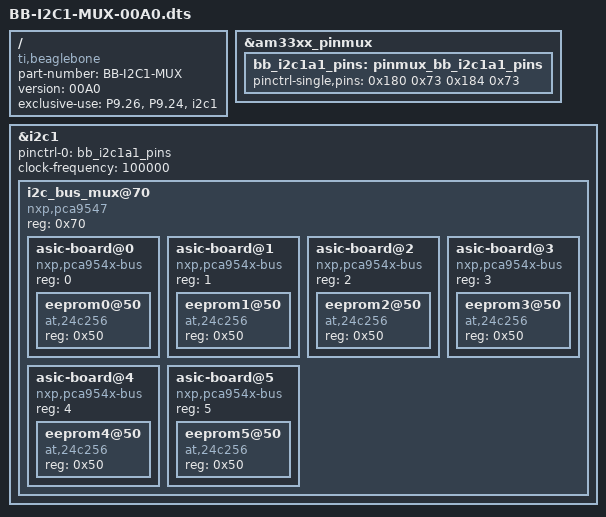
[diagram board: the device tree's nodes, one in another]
/*
 * Copyright (C) 2013 CircuitCo
 *
 * Virtual cape for I2C1 on connector pins P9.26 P9.24 (ALT config #1)
 *
 * This program is free software; you can redistribute it and/or modify
 * it under the terms of the GNU General Public License version 2 as
 * published by the Free Software Foundation.
 */
/dts-v1/;
/plugin/;

/ {
	compatible = "ti,beaglebone", "ti,beaglebone-black";

	/* identification */
	part-number = "BB-I2C1-MUX";
	version = "00A0";

	/* state the resources this cape uses */
	exclusive-use =
		/* the pin header uses */
		"P9.26",	/* i2c1_sda */
		"P9.24",	/* i2c1_scl */
		/* the hardware ip uses */
		"i2c1";

	fragment@0 {
		target = <&am33xx_pinmux>;
		__overlay__ {
			bb_i2c1a1_pins: pinmux_bb_i2c1a1_pins {
				pinctrl-single,pins = <
					0x180 0x73	/* uart1_rxd.i2c1_sda, SLEWCTRL_SLOW | INPUT_PULLUP | MODE3 */
					0x184 0x73	/* uart1_txdi2c1_scl, SLEWCTRL_SLOW | INPUT_PULLUP | MODE3 */
				>;
			};
		};
	};

	fragment@1 {
		target = <&i2c1>;	/* i2c1 is numbered correctly */
		__overlay__ {
			status = "okay";
			pinctrl-names = "default";
			pinctrl-0 = <&bb_i2c1a1_pins>;

			/* this is the configuration part */
			clock-frequency = <100000>;	

			#address-cells = <1>;
			#size-cells = <0>;

			i2c_bus_mux@70 {
				compatible = "nxp,pca9547";
				reg = <0x70>;
				#address-cells = <1>;
				#size-cells = <0>;

				asic-board@0 {
					compatible = "nxp,pca954x-bus";
					#address-cells = <1>;
					#size-cells = <0>;
					reg = <0>;

					eeprom0@50 {
						compatible = 
"at,24c256";
						reg = <0x50>;
					};
				};

				asic-board@1 {
					compatible = "nxp,pca954x-bus";
					#address-cells = <1>;
					#size-cells = <0>;
					reg = <1>;

                                        eeprom1@50 {
                                                compatible =
"at,24c256";
                                                reg = <0x50>;
                                        };
				};

				asic-board@2 {
					compatible = "nxp,pca954x-bus";
					#address-cells = <1>;
					#size-cells = <0>;
					reg = <2>;

                                        eeprom2@50 {
                                                compatible =
"at,24c256";
                                                reg = <0x50>;
                                        };
				};

                                asic-board@3 {
					compatible = "nxp,pca954x-bus";
					#address-cells = <1>;
					#size-cells = <0>;
					reg = <3>;

					eeprom3@50 {
						compatible =
"at,24c256";
						reg = <0x50>;
					};
				};

                                asic-board@4 {
                                        compatible = "nxp,pca954x-bus";
                                        #address-cells = <1>;
                                        #size-cells = <0>;
                                        reg = <4>;

                                        eeprom4@50 {
                                                compatible =
"at,24c256";
                                                reg = <0x50>;
                                        };
				};

                                asic-board@5 {
                                        compatible = "nxp,pca954x-bus";
                                        #address-cells = <1>;
                                        #size-cells = <0>;
                                        reg = <5>;

                                        eeprom5@50 {
                                                compatible =
"at,24c256";
                                                reg = <0x50>;
                                        };
                                };
			};
		};
	};
};
